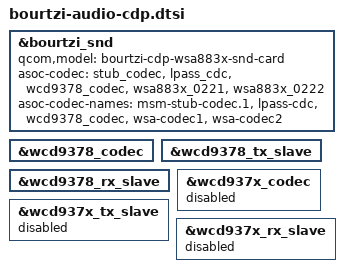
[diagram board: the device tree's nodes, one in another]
// SPDX-License-Identifier: BSD-3-Clause
/*
 * Copyright (c) Qualcomm Technologies, Inc. and/or its subsidiaries.
 */
#include "bourtzi-audio-overlay.dtsi"

&bourtzi_snd {
        qcom,model = "bourtzi-cdp-wsa883x-snd-card";
        asoc-codec = <&stub_codec>, <&lpass_cdc>,
                     <&wcd9378_codec>,
                     <&wsa883x_0221>, <&wsa883x_0222>;
        asoc-codec-names = "msm-stub-codec.1", "lpass-cdc",
                           "wcd9378_codec",
                           "wsa-codec1", "wsa-codec2";
};

&wcd9378_codec {
        status = "okay";
};

&wcd9378_tx_slave {
        status = "okay";
};

&wcd9378_rx_slave {
        status = "okay";
};

&wcd937x_codec {
        status = "disabled";
};

&wcd937x_tx_slave {
        status = "disabled";
};

&wcd937x_rx_slave {
        status = "disabled";
};
